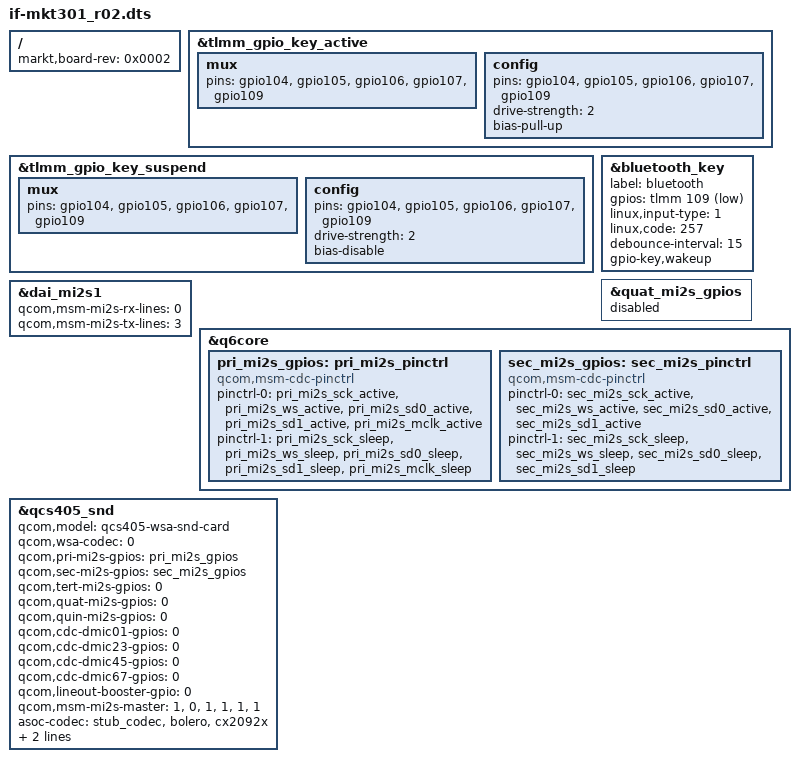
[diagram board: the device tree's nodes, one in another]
/dts-v1/;

#include "if-mkt301_base.dtsi"

/ {
	markt,board-rev = <0x0002>;
};

&tlmm_gpio_key_active {
    mux {
        pins = "gpio104", "gpio105", "gpio106", "gpio107", "gpio109";
    };

    config {
        pins = "gpio104", "gpio105", "gpio106", "gpio107", "gpio109";
        drive-strength = <2>;
        bias-pull-up;
    };
};

&tlmm_gpio_key_suspend {
    mux {
        pins = "gpio104", "gpio105", "gpio106", "gpio107", "gpio109";
    };

    config {
        pins = "gpio104", "gpio105", "gpio106", "gpio107", "gpio109";
        drive-strength = <2>;
        bias-disable;
    };
};

&bluetooth_key {
    label = "bluetooth";
    gpios = <&tlmm 109 GPIO_ACTIVE_LOW>;
    linux,input-type = <1>;
    linux,code = <257>;
    debounce-interval = <15>;
    gpio-key,wakeup;
};

&quat_mi2s_gpios {
    status = "disabled";
};

/* Secondary MI2S */
&dai_mi2s1 {
    qcom,msm-mi2s-rx-lines = <0>;
    qcom,msm-mi2s-tx-lines = <3>;
};

&q6core {
    pri_mi2s_gpios: pri_mi2s_pinctrl {
        compatible = "qcom,msm-cdc-pinctrl";
        pinctrl-names = "aud_active", "aud_sleep";
        pinctrl-0 = <&pri_mi2s_sck_active &pri_mi2s_ws_active
                    &pri_mi2s_sd0_active &pri_mi2s_sd1_active 
					&pri_mi2s_mclk_active>;
        pinctrl-1 = <&pri_mi2s_sck_sleep &pri_mi2s_ws_sleep
                    &pri_mi2s_sd0_sleep &pri_mi2s_sd1_sleep 
					&pri_mi2s_mclk_sleep>;
    };

    sec_mi2s_gpios: sec_mi2s_pinctrl {
        compatible = "qcom,msm-cdc-pinctrl";
        pinctrl-names = "aud_active", "aud_sleep";
        pinctrl-0 = <&sec_mi2s_sck_active &sec_mi2s_ws_active 
                    &sec_mi2s_sd0_active &sec_mi2s_sd1_active>;
        pinctrl-1 = <&sec_mi2s_sck_sleep &sec_mi2s_ws_sleep
                    &sec_mi2s_sd0_sleep &sec_mi2s_sd1_sleep>;
    };
};

&qcs405_snd {
    qcom,model = "qcs405-wsa-snd-card";
    qcom,wsa-codec = <0>;


    /* mi2s gpios */
    qcom,pri-mi2s-gpios = <&pri_mi2s_gpios>;
    qcom,sec-mi2s-gpios = <&sec_mi2s_gpios>;
    qcom,tert-mi2s-gpios = <0>;
    qcom,quat-mi2s-gpios = <0>;
    qcom,quin-mi2s-gpios = <0>;

    /* dmic gpios  */
    qcom,cdc-dmic01-gpios = <0>;
    qcom,cdc-dmic23-gpios = <0>;
    qcom,cdc-dmic45-gpios = <0>;
    qcom,cdc-dmic67-gpios = <0>;

    qcom,lineout-booster-gpio = <0>;

    /* mi2s master/slave */
    qcom,msm-mi2s-master = <1>, /* PRI */
                           <0>, /* SEC */
                           <1>, /* TERT */
                           <1>, /* QUAT */
                           <1>, /* QUIN */
                           <1>; /* SEN */
						   
	asoc-codec = <&stub_codec>, <&bolero>, <&cx2092x>;
    asoc-codec-names = "msm-stub-codec.1", "bolero_codec", "cx2092x.6-0041";
    
};
